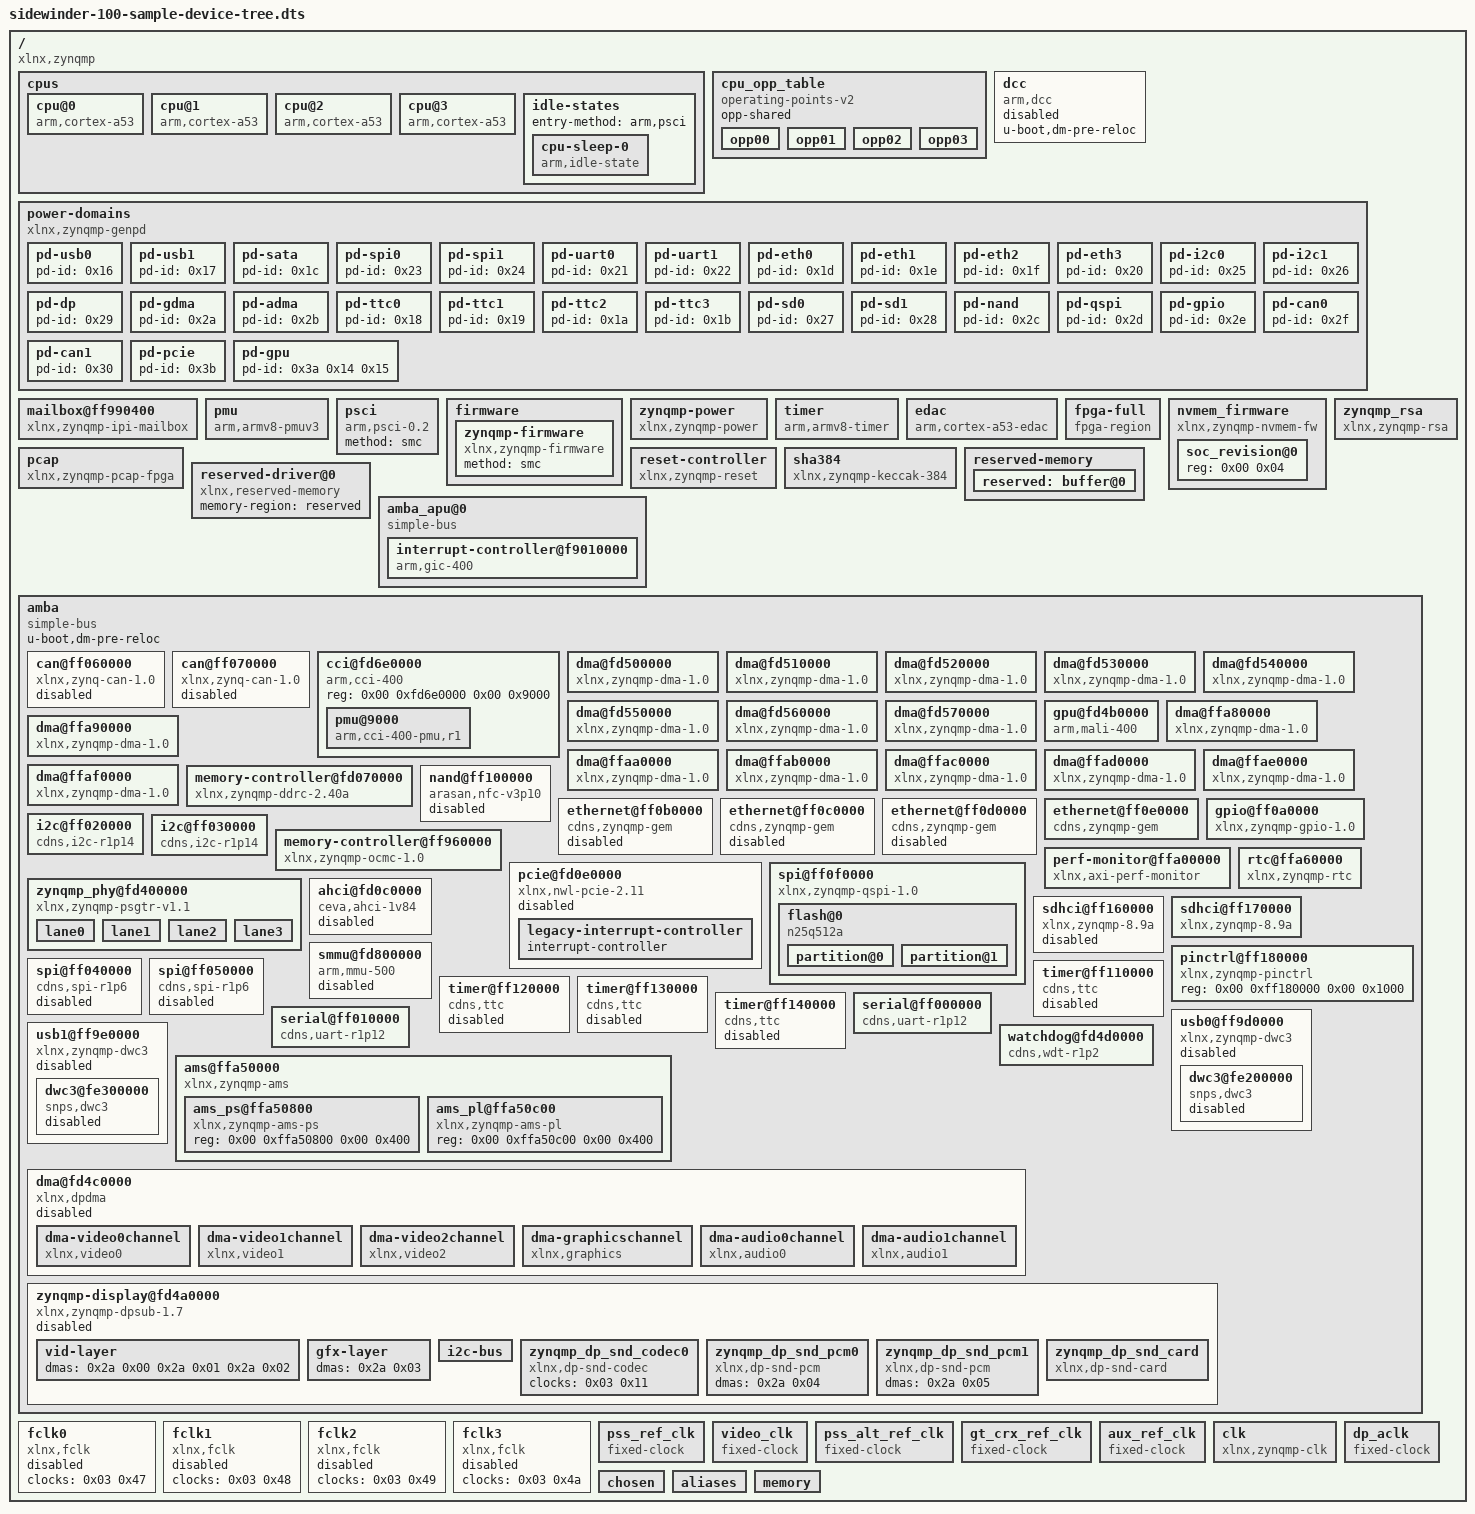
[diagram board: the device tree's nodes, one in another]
/dts-v1/;

/ {
	compatible = "xlnx,zynqmp";
	#address-cells = < 0x02 >;
	#size-cells = < 0x02 >;

	cpus {
		#address-cells = < 0x01 >;
		#size-cells = < 0x00 >;

		cpu@0 {
			compatible = "arm,cortex-a53\0arm,armv8";
			device_type = "cpu";
			enable-method = "psci";
			operating-points-v2 = < 0x01 >;
			reg = < 0x00 >;
			cpu-idle-states = < 0x02 >;
			clocks = < 0x03 0x0a >;
			phandle = < 0x33 >;
		};

		cpu@1 {
			compatible = "arm,cortex-a53\0arm,armv8";
			device_type = "cpu";
			enable-method = "psci";
			reg = < 0x01 >;
			operating-points-v2 = < 0x01 >;
			cpu-idle-states = < 0x02 >;
			phandle = < 0x34 >;
		};

		cpu@2 {
			compatible = "arm,cortex-a53\0arm,armv8";
			device_type = "cpu";
			enable-method = "psci";
			reg = < 0x02 >;
			operating-points-v2 = < 0x01 >;
			cpu-idle-states = < 0x02 >;
			phandle = < 0x35 >;
		};

		cpu@3 {
			compatible = "arm,cortex-a53\0arm,armv8";
			device_type = "cpu";
			enable-method = "psci";
			reg = < 0x03 >;
			operating-points-v2 = < 0x01 >;
			cpu-idle-states = < 0x02 >;
			phandle = < 0x36 >;
		};

		idle-states {
			entry-method = "arm,psci";

			cpu-sleep-0 {
				compatible = "arm,idle-state";
				arm,psci-suspend-param = < 0x40000000 >;
				local-timer-stop;
				entry-latency-us = < 0x12c >;
				exit-latency-us = < 0x258 >;
				min-residency-us = < 0x2710 >;
				phandle = < 0x02 >;
			};
		};
	};

	cpu_opp_table {
		compatible = "operating-points-v2";
		opp-shared;
		phandle = < 0x01 >;

		opp00 {
			opp-hz = < 0x00 0x47868bf4 >;
			opp-microvolt = < 0xf4240 >;
			clock-latency-ns = < 0x7a120 >;
		};

		opp01 {
			opp-hz = < 0x00 0x23c345fa >;
			opp-microvolt = < 0xf4240 >;
			clock-latency-ns = < 0x7a120 >;
		};

		opp02 {
			opp-hz = < 0x00 0x17d783fc >;
			opp-microvolt = < 0xf4240 >;
			clock-latency-ns = < 0x7a120 >;
		};

		opp03 {
			opp-hz = < 0x00 0x11e1a2fd >;
			opp-microvolt = < 0xf4240 >;
			clock-latency-ns = < 0x7a120 >;
		};
	};

	dcc {
		compatible = "arm,dcc";
		status = "disabled";
		u-boot,dm-pre-reloc;
		phandle = < 0x37 >;
	};

	power-domains {
		compatible = "xlnx,zynqmp-genpd";

		pd-usb0 {
			#power-domain-cells = < 0x00 >;
			pd-id = < 0x16 >;
			phandle = < 0x26 >;
		};

		pd-usb1 {
			#power-domain-cells = < 0x00 >;
			pd-id = < 0x17 >;
			phandle = < 0x27 >;
		};

		pd-sata {
			#power-domain-cells = < 0x00 >;
			pd-id = < 0x1c >;
			phandle = < 0x1b >;
		};

		pd-spi0 {
			#power-domain-cells = < 0x00 >;
			pd-id = < 0x23 >;
			phandle = < 0x1e >;
		};

		pd-spi1 {
			#power-domain-cells = < 0x00 >;
			pd-id = < 0x24 >;
			phandle = < 0x1f >;
		};

		pd-uart0 {
			#power-domain-cells = < 0x00 >;
			pd-id = < 0x21 >;
			phandle = < 0x24 >;
		};

		pd-uart1 {
			#power-domain-cells = < 0x00 >;
			pd-id = < 0x22 >;
			phandle = < 0x25 >;
		};

		pd-eth0 {
			#power-domain-cells = < 0x00 >;
			pd-id = < 0x1d >;
			phandle = < 0x0e >;
		};

		pd-eth1 {
			#power-domain-cells = < 0x00 >;
			pd-id = < 0x1e >;
			phandle = < 0x0f >;
		};

		pd-eth2 {
			#power-domain-cells = < 0x00 >;
			pd-id = < 0x1f >;
			phandle = < 0x10 >;
		};

		pd-eth3 {
			#power-domain-cells = < 0x00 >;
			pd-id = < 0x20 >;
			phandle = < 0x11 >;
		};

		pd-i2c0 {
			#power-domain-cells = < 0x00 >;
			pd-id = < 0x25 >;
			phandle = < 0x13 >;
		};

		pd-i2c1 {
			#power-domain-cells = < 0x00 >;
			pd-id = < 0x26 >;
			phandle = < 0x14 >;
		};

		pd-dp {
			#power-domain-cells = < 0x00 >;
			pd-id = < 0x29 >;
			phandle = < 0x28 >;
		};

		pd-gdma {
			#power-domain-cells = < 0x00 >;
			pd-id = < 0x2a >;
			phandle = < 0x0a >;
		};

		pd-adma {
			#power-domain-cells = < 0x00 >;
			pd-id = < 0x2b >;
			phandle = < 0x0c >;
		};

		pd-ttc0 {
			#power-domain-cells = < 0x00 >;
			pd-id = < 0x18 >;
			phandle = < 0x20 >;
		};

		pd-ttc1 {
			#power-domain-cells = < 0x00 >;
			pd-id = < 0x19 >;
			phandle = < 0x21 >;
		};

		pd-ttc2 {
			#power-domain-cells = < 0x00 >;
			pd-id = < 0x1a >;
			phandle = < 0x22 >;
		};

		pd-ttc3 {
			#power-domain-cells = < 0x00 >;
			pd-id = < 0x1b >;
			phandle = < 0x23 >;
		};

		pd-sd0 {
			#power-domain-cells = < 0x00 >;
			pd-id = < 0x27 >;
			phandle = < 0x1c >;
		};

		pd-sd1 {
			#power-domain-cells = < 0x00 >;
			pd-id = < 0x28 >;
			phandle = < 0x1d >;
		};

		pd-nand {
			#power-domain-cells = < 0x00 >;
			pd-id = < 0x2c >;
			phandle = < 0x0d >;
		};

		pd-qspi {
			#power-domain-cells = < 0x00 >;
			pd-id = < 0x2d >;
			phandle = < 0x18 >;
		};

		pd-gpio {
			#power-domain-cells = < 0x00 >;
			pd-id = < 0x2e >;
			phandle = < 0x12 >;
		};

		pd-can0 {
			#power-domain-cells = < 0x00 >;
			pd-id = < 0x2f >;
			phandle = < 0x07 >;
		};

		pd-can1 {
			#power-domain-cells = < 0x00 >;
			pd-id = < 0x30 >;
			phandle = < 0x08 >;
		};

		pd-pcie {
			#power-domain-cells = < 0x00 >;
			pd-id = < 0x3b >;
			phandle = < 0x17 >;
		};

		pd-gpu {
			#power-domain-cells = < 0x00 >;
			pd-id = < 0x3a 0x14 0x15 >;
			phandle = < 0x0b >;
		};
	};

	mailbox@ff990400 {
		compatible = "xlnx,zynqmp-ipi-mailbox";
		reg = < 0x00 0xff9905c0 0x00 0x20 0x00 0xff9905e0 0x00 0x20 0x00 0xff990e80 0x00 0x20 0x00 0xff990ea0 0x00 0x20 >;
		reg-names = "local_request_region\0local_response_region\0remote_request_region\0remote_response_region";
		#mbox-cells = < 0x01 >;
		xlnx,ipi-ids = < 0x00 0x04 >;
		interrupt-parent = < 0x04 >;
		interrupts = < 0x00 0x23 0x04 >;
		phandle = < 0x05 >;
	};

	pmu {
		compatible = "arm,armv8-pmuv3";
		interrupt-parent = < 0x04 >;
		interrupts = < 0x00 0x8f 0x04 0x00 0x90 0x04 0x00 0x91 0x04 0x00 0x92 0x04 >;
	};

	psci {
		compatible = "arm,psci-0.2";
		method = "smc";
	};

	firmware {

		zynqmp-firmware {
			compatible = "xlnx,zynqmp-firmware";
			method = "smc";
			phandle = < 0x38 >;
		};
	};

	zynqmp-power {
		compatible = "xlnx,zynqmp-power";
		mboxes = < 0x05 0x00 0x05 0x01 >;
		mbox-names = "tx\0rx";
		phandle = < 0x39 >;
	};

	timer {
		compatible = "arm,armv8-timer";
		interrupt-parent = < 0x04 >;
		interrupts = < 0x01 0x0d 0xf08 0x01 0x0e 0xf08 0x01 0x0b 0xf08 0x01 0x0a 0xf08 >;
	};

	edac {
		compatible = "arm,cortex-a53-edac";
	};

	fpga-full {
		compatible = "fpga-region";
        vendorName = "fidus.com";
        boardName = "sidewinder-100";
		fpga-mgr = < 0x06 >;
		#address-cells = < 0x02 >;
		#size-cells = < 0x02 >;
		phandle = < 0x3a >;
	};

	nvmem_firmware {
		compatible = "xlnx,zynqmp-nvmem-fw";
		#address-cells = < 0x01 >;
		#size-cells = < 0x01 >;

		soc_revision@0 {
			reg = < 0x00 0x04 >;
			phandle = < 0x19 >;
		};
	};

	pcap {
		compatible = "xlnx,zynqmp-pcap-fpga";
		phandle = < 0x06 >;
	};

	reset-controller {
		compatible = "xlnx,zynqmp-reset";
		#reset-cells = < 0x01 >;
		phandle = < 0x1a >;
	};

	zynqmp_rsa {
		compatible = "xlnx,zynqmp-rsa";
		phandle = < 0x3b >;
	};

	sha384 {
		compatible = "xlnx,zynqmp-keccak-384";
		phandle = < 0x3c >;
	};

	reserved-memory {
		#address-cells = <2>;
		#size-cells = <2>;
		ranges;
		
		reserved: buffer@0 {
			no-map;
			reg = <0x0 0x90000000 0x0 0x10000000>;
		};
	};
	
    reserved-driver@0 {
		compatible = "xlnx,reserved-memory";
		memory-region = <&reserved>;
	};

	amba_apu@0 {
		compatible = "simple-bus";
		#address-cells = < 0x02 >;
		#size-cells = < 0x01 >;
		ranges = < 0x00 0x00 0x00 0x00 0xffffffff >;
		phandle = < 0x3d >;

		interrupt-controller@f9010000 {
			compatible = "arm,gic-400\0arm,cortex-a15-gic";
			#interrupt-cells = < 0x03 >;
			reg = < 0x00 0xf9010000 0x10000 0x00 0xf9020000 0x20000 0x00 0xf9040000 0x20000 0x00 0xf9060000 0x20000 >;
			interrupt-controller;
			interrupt-parent = < 0x04 >;
			interrupts = < 0x01 0x09 0xf04 >;
			phandle = < 0x04 >;
		};
	};

	amba {
		compatible = "simple-bus";
		u-boot,dm-pre-reloc;
		#address-cells = < 0x02 >;
		#size-cells = < 0x02 >;
		ranges;
		phandle = < 0x3e >;

		can@ff060000 {
			compatible = "xlnx,zynq-can-1.0";
			status = "disabled";
			clock-names = "can_clk\0pclk";
			reg = < 0x00 0xff060000 0x00 0x1000 >;
			interrupts = < 0x00 0x17 0x04 >;
			interrupt-parent = < 0x04 >;
			tx-fifo-depth = < 0x40 >;
			rx-fifo-depth = < 0x40 >;
			power-domains = < 0x07 >;
			clocks = < 0x03 0x3f 0x03 0x1f >;
			phandle = < 0x3f >;
		};

		can@ff070000 {
			compatible = "xlnx,zynq-can-1.0";
			status = "disabled";
			clock-names = "can_clk\0pclk";
			reg = < 0x00 0xff070000 0x00 0x1000 >;
			interrupts = < 0x00 0x18 0x04 >;
			interrupt-parent = < 0x04 >;
			tx-fifo-depth = < 0x40 >;
			rx-fifo-depth = < 0x40 >;
			power-domains = < 0x08 >;
			clocks = < 0x03 0x40 0x03 0x1f >;
			phandle = < 0x40 >;
		};

		cci@fd6e0000 {
			compatible = "arm,cci-400";
			reg = < 0x00 0xfd6e0000 0x00 0x9000 >;
			ranges = < 0x00 0x00 0xfd6e0000 0x10000 >;
			#address-cells = < 0x01 >;
			#size-cells = < 0x01 >;
			phandle = < 0x41 >;

			pmu@9000 {
				compatible = "arm,cci-400-pmu,r1";
				reg = < 0x9000 0x5000 >;
				interrupt-parent = < 0x04 >;
				interrupts = < 0x00 0x7b 0x04 0x00 0x7b 0x04 0x00 0x7b 0x04 0x00 0x7b 0x04 0x00 0x7b 0x04 >;
			};
		};

		dma@fd500000 {
			status = "okay";
			compatible = "xlnx,zynqmp-dma-1.0";
			reg = < 0x00 0xfd500000 0x00 0x1000 >;
			interrupt-parent = < 0x04 >;
			interrupts = < 0x00 0x7c 0x04 >;
			clock-names = "clk_main\0clk_apb";
			xlnx,bus-width = < 0x80 >;
			#stream-id-cells = < 0x01 >;
			iommus = < 0x09 0x14e8 >;
			power-domains = < 0x0a >;
			clocks = < 0x03 0x13 0x03 0x1f >;
			phandle = < 0x42 >;
		};

		dma@fd510000 {
			status = "okay";
			compatible = "xlnx,zynqmp-dma-1.0";
			reg = < 0x00 0xfd510000 0x00 0x1000 >;
			interrupt-parent = < 0x04 >;
			interrupts = < 0x00 0x7d 0x04 >;
			clock-names = "clk_main\0clk_apb";
			xlnx,bus-width = < 0x80 >;
			#stream-id-cells = < 0x01 >;
			iommus = < 0x09 0x14e9 >;
			power-domains = < 0x0a >;
			clocks = < 0x03 0x13 0x03 0x1f >;
			phandle = < 0x43 >;
		};

		dma@fd520000 {
			status = "okay";
			compatible = "xlnx,zynqmp-dma-1.0";
			reg = < 0x00 0xfd520000 0x00 0x1000 >;
			interrupt-parent = < 0x04 >;
			interrupts = < 0x00 0x7e 0x04 >;
			clock-names = "clk_main\0clk_apb";
			xlnx,bus-width = < 0x80 >;
			#stream-id-cells = < 0x01 >;
			iommus = < 0x09 0x14ea >;
			power-domains = < 0x0a >;
			clocks = < 0x03 0x13 0x03 0x1f >;
			phandle = < 0x44 >;
		};

		dma@fd530000 {
			status = "okay";
			compatible = "xlnx,zynqmp-dma-1.0";
			reg = < 0x00 0xfd530000 0x00 0x1000 >;
			interrupt-parent = < 0x04 >;
			interrupts = < 0x00 0x7f 0x04 >;
			clock-names = "clk_main\0clk_apb";
			xlnx,bus-width = < 0x80 >;
			#stream-id-cells = < 0x01 >;
			iommus = < 0x09 0x14eb >;
			power-domains = < 0x0a >;
			clocks = < 0x03 0x13 0x03 0x1f >;
			phandle = < 0x45 >;
		};

		dma@fd540000 {
			status = "okay";
			compatible = "xlnx,zynqmp-dma-1.0";
			reg = < 0x00 0xfd540000 0x00 0x1000 >;
			interrupt-parent = < 0x04 >;
			interrupts = < 0x00 0x80 0x04 >;
			clock-names = "clk_main\0clk_apb";
			xlnx,bus-width = < 0x80 >;
			#stream-id-cells = < 0x01 >;
			iommus = < 0x09 0x14ec >;
			power-domains = < 0x0a >;
			clocks = < 0x03 0x13 0x03 0x1f >;
			phandle = < 0x46 >;
		};

		dma@fd550000 {
			status = "okay";
			compatible = "xlnx,zynqmp-dma-1.0";
			reg = < 0x00 0xfd550000 0x00 0x1000 >;
			interrupt-parent = < 0x04 >;
			interrupts = < 0x00 0x81 0x04 >;
			clock-names = "clk_main\0clk_apb";
			xlnx,bus-width = < 0x80 >;
			#stream-id-cells = < 0x01 >;
			iommus = < 0x09 0x14ed >;
			power-domains = < 0x0a >;
			clocks = < 0x03 0x13 0x03 0x1f >;
			phandle = < 0x47 >;
		};

		dma@fd560000 {
			status = "okay";
			compatible = "xlnx,zynqmp-dma-1.0";
			reg = < 0x00 0xfd560000 0x00 0x1000 >;
			interrupt-parent = < 0x04 >;
			interrupts = < 0x00 0x82 0x04 >;
			clock-names = "clk_main\0clk_apb";
			xlnx,bus-width = < 0x80 >;
			#stream-id-cells = < 0x01 >;
			iommus = < 0x09 0x14ee >;
			power-domains = < 0x0a >;
			clocks = < 0x03 0x13 0x03 0x1f >;
			phandle = < 0x48 >;
		};

		dma@fd570000 {
			status = "okay";
			compatible = "xlnx,zynqmp-dma-1.0";
			reg = < 0x00 0xfd570000 0x00 0x1000 >;
			interrupt-parent = < 0x04 >;
			interrupts = < 0x00 0x83 0x04 >;
			clock-names = "clk_main\0clk_apb";
			xlnx,bus-width = < 0x80 >;
			#stream-id-cells = < 0x01 >;
			iommus = < 0x09 0x14ef >;
			power-domains = < 0x0a >;
			clocks = < 0x03 0x13 0x03 0x1f >;
			phandle = < 0x49 >;
		};

		gpu@fd4b0000 {
			status = "okay";
			compatible = "arm,mali-400\0arm,mali-utgard";
			reg = < 0x00 0xfd4b0000 0x00 0x10000 >;
			interrupt-parent = < 0x04 >;
			interrupts = < 0x00 0x84 0x04 0x00 0x84 0x04 0x00 0x84 0x04 0x00 0x84 0x04 0x00 0x84 0x04 0x00 0x84 0x04 >;
			interrupt-names = "IRQGP\0IRQGPMMU\0IRQPP0\0IRQPPMMU0\0IRQPP1\0IRQPPMMU1";
			clock-names = "gpu\0gpu_pp0\0gpu_pp1";
			power-domains = < 0x0b >;
			clocks = < 0x03 0x18 0x03 0x19 0x03 0x1a >;
			phandle = < 0x4a >;
		};

		dma@ffa80000 {
			status = "okay";
			compatible = "xlnx,zynqmp-dma-1.0";
			reg = < 0x00 0xffa80000 0x00 0x1000 >;
			interrupt-parent = < 0x04 >;
			interrupts = < 0x00 0x4d 0x04 >;
			clock-names = "clk_main\0clk_apb";
			xlnx,bus-width = < 0x40 >;
			#stream-id-cells = < 0x01 >;
			power-domains = < 0x0c >;
			clocks = < 0x03 0x44 0x03 0x1f >;
			phandle = < 0x4b >;
		};

		dma@ffa90000 {
			status = "okay";
			compatible = "xlnx,zynqmp-dma-1.0";
			reg = < 0x00 0xffa90000 0x00 0x1000 >;
			interrupt-parent = < 0x04 >;
			interrupts = < 0x00 0x4e 0x04 >;
			clock-names = "clk_main\0clk_apb";
			xlnx,bus-width = < 0x40 >;
			#stream-id-cells = < 0x01 >;
			power-domains = < 0x0c >;
			clocks = < 0x03 0x44 0x03 0x1f >;
			phandle = < 0x4c >;
		};

		dma@ffaa0000 {
			status = "okay";
			compatible = "xlnx,zynqmp-dma-1.0";
			reg = < 0x00 0xffaa0000 0x00 0x1000 >;
			interrupt-parent = < 0x04 >;
			interrupts = < 0x00 0x4f 0x04 >;
			clock-names = "clk_main\0clk_apb";
			xlnx,bus-width = < 0x40 >;
			#stream-id-cells = < 0x01 >;
			power-domains = < 0x0c >;
			clocks = < 0x03 0x44 0x03 0x1f >;
			phandle = < 0x4d >;
		};

		dma@ffab0000 {
			status = "okay";
			compatible = "xlnx,zynqmp-dma-1.0";
			reg = < 0x00 0xffab0000 0x00 0x1000 >;
			interrupt-parent = < 0x04 >;
			interrupts = < 0x00 0x50 0x04 >;
			clock-names = "clk_main\0clk_apb";
			xlnx,bus-width = < 0x40 >;
			#stream-id-cells = < 0x01 >;
			power-domains = < 0x0c >;
			clocks = < 0x03 0x44 0x03 0x1f >;
			phandle = < 0x4e >;
		};

		dma@ffac0000 {
			status = "okay";
			compatible = "xlnx,zynqmp-dma-1.0";
			reg = < 0x00 0xffac0000 0x00 0x1000 >;
			interrupt-parent = < 0x04 >;
			interrupts = < 0x00 0x51 0x04 >;
			clock-names = "clk_main\0clk_apb";
			xlnx,bus-width = < 0x40 >;
			#stream-id-cells = < 0x01 >;
			power-domains = < 0x0c >;
			clocks = < 0x03 0x44 0x03 0x1f >;
			phandle = < 0x4f >;
		};

		dma@ffad0000 {
			status = "okay";
			compatible = "xlnx,zynqmp-dma-1.0";
			reg = < 0x00 0xffad0000 0x00 0x1000 >;
			interrupt-parent = < 0x04 >;
			interrupts = < 0x00 0x52 0x04 >;
			clock-names = "clk_main\0clk_apb";
			xlnx,bus-width = < 0x40 >;
			#stream-id-cells = < 0x01 >;
			power-domains = < 0x0c >;
			clocks = < 0x03 0x44 0x03 0x1f >;
			phandle = < 0x50 >;
		};

		dma@ffae0000 {
			status = "okay";
			compatible = "xlnx,zynqmp-dma-1.0";
			reg = < 0x00 0xffae0000 0x00 0x1000 >;
			interrupt-parent = < 0x04 >;
			interrupts = < 0x00 0x53 0x04 >;
			clock-names = "clk_main\0clk_apb";
			xlnx,bus-width = < 0x40 >;
			#stream-id-cells = < 0x01 >;
			power-domains = < 0x0c >;
			clocks = < 0x03 0x44 0x03 0x1f >;
			phandle = < 0x51 >;
		};

		dma@ffaf0000 {
			status = "okay";
			compatible = "xlnx,zynqmp-dma-1.0";
			reg = < 0x00 0xffaf0000 0x00 0x1000 >;
			interrupt-parent = < 0x04 >;
			interrupts = < 0x00 0x54 0x04 >;
			clock-names = "clk_main\0clk_apb";
			xlnx,bus-width = < 0x40 >;
			#stream-id-cells = < 0x01 >;
			power-domains = < 0x0c >;
			clocks = < 0x03 0x44 0x03 0x1f >;
			phandle = < 0x52 >;
		};

		memory-controller@fd070000 {
			compatible = "xlnx,zynqmp-ddrc-2.40a";
			reg = < 0x00 0xfd070000 0x00 0x30000 >;
			interrupt-parent = < 0x04 >;
			interrupts = < 0x00 0x70 0x04 >;
			phandle = < 0x53 >;
		};

		nand@ff100000 {
			compatible = "arasan,nfc-v3p10";
			status = "disabled";
			reg = < 0x00 0xff100000 0x00 0x1000 >;
			clock-names = "clk_sys\0clk_flash";
			interrupt-parent = < 0x04 >;
			interrupts = < 0x00 0x0e 0x04 >;
			#address-cells = < 0x01 >;
			#size-cells = < 0x00 >;
			#stream-id-cells = < 0x01 >;
			iommus = < 0x09 0x872 >;
			power-domains = < 0x0d >;
			clocks = < 0x03 0x3c 0x03 0x1f >;
			phandle = < 0x54 >;
		};

		ethernet@ff0b0000 {
			compatible = "cdns,zynqmp-gem";
			status = "disabled";
			interrupt-parent = < 0x04 >;
			interrupts = < 0x00 0x39 0x04 0x00 0x39 0x04 >;
			reg = < 0x00 0xff0b0000 0x00 0x1000 >;
			clock-names = "pclk\0hclk\0tx_clk\0rx_clk\0tsu_clk";
			#address-cells = < 0x01 >;
			#size-cells = < 0x00 >;
			#stream-id-cells = < 0x01 >;
			iommus = < 0x09 0x874 >;
			power-domains = < 0x0e >;
			clocks = < 0x03 0x1f 0x03 0x31 0x03 0x2d 0x03 0x31 0x03 0x2c >;
			phandle = < 0x55 >;
		};

		ethernet@ff0c0000 {
			compatible = "cdns,zynqmp-gem";
			status = "disabled";
			interrupt-parent = < 0x04 >;
			interrupts = < 0x00 0x3b 0x04 0x00 0x3b 0x04 >;
			reg = < 0x00 0xff0c0000 0x00 0x1000 >;
			clock-names = "pclk\0hclk\0tx_clk\0rx_clk\0tsu_clk";
			#address-cells = < 0x01 >;
			#size-cells = < 0x00 >;
			#stream-id-cells = < 0x01 >;
			iommus = < 0x09 0x875 >;
			power-domains = < 0x0f >;
			clocks = < 0x03 0x1f 0x03 0x32 0x03 0x2e 0x03 0x32 0x03 0x2c >;
			phandle = < 0x56 >;
		};

		ethernet@ff0d0000 {
			compatible = "cdns,zynqmp-gem";
			status = "disabled";
			interrupt-parent = < 0x04 >;
			interrupts = < 0x00 0x3d 0x04 0x00 0x3d 0x04 >;
			reg = < 0x00 0xff0d0000 0x00 0x1000 >;
			clock-names = "pclk\0hclk\0tx_clk\0rx_clk\0tsu_clk";
			#address-cells = < 0x01 >;
			#size-cells = < 0x00 >;
			#stream-id-cells = < 0x01 >;
			iommus = < 0x09 0x876 >;
			power-domains = < 0x10 >;
			clocks = < 0x03 0x1f 0x03 0x33 0x03 0x2f 0x03 0x33 0x03 0x2c >;
			phandle = < 0x57 >;
		};

		ethernet@ff0e0000 {
			compatible = "cdns,zynqmp-gem";
			status = "okay";
			interrupt-parent = < 0x04 >;
			interrupts = < 0x00 0x3f 0x04 0x00 0x3f 0x04 >;
			reg = < 0x00 0xff0e0000 0x00 0x1000 >;
			clock-names = "pclk\0hclk\0tx_clk\0rx_clk\0tsu_clk";
			#address-cells = < 0x01 >;
			#size-cells = < 0x00 >;
			#stream-id-cells = < 0x01 >;
			iommus = < 0x09 0x877 >;
			power-domains = < 0x11 >;
			clocks = < 0x03 0x1f 0x03 0x34 0x03 0x30 0x03 0x34 0x03 0x2c >;
			phy-mode = "rgmii-id";
			xlnx,ptp-enet-clock = < 0x00 >;
			phandle = < 0x58 >;
		};

		gpio@ff0a0000 {
			compatible = "xlnx,zynqmp-gpio-1.0";
			status = "okay";
			#gpio-cells = < 0x02 >;
			interrupt-parent = < 0x04 >;
			interrupts = < 0x00 0x10 0x04 >;
			interrupt-controller;
			#interrupt-cells = < 0x02 >;
			reg = < 0x00 0xff0a0000 0x00 0x1000 >;
			gpio-controller;
			power-domains = < 0x12 >;
			clocks = < 0x03 0x1f >;
			emio-gpio-width = < 0x20 >;
			gpio-mask-high = < 0x00 >;
			gpio-mask-low = < 0x5600 >;
			phandle = < 0x59 >;
		};

		i2c@ff020000 {
			compatible = "cdns,i2c-r1p14\0cdns,i2c-r1p10";
			status = "okay";
			interrupt-parent = < 0x04 >;
			interrupts = < 0x00 0x11 0x04 >;
			reg = < 0x00 0xff020000 0x00 0x1000 >;
			#address-cells = < 0x01 >;
			#size-cells = < 0x00 >;
			power-domains = < 0x13 >;
			clocks = < 0x03 0x3d >;
			clock-frequency = < 0x61a80 >;
			phandle = < 0x5a >;
		};

		i2c@ff030000 {
			compatible = "cdns,i2c-r1p14\0cdns,i2c-r1p10";
			status = "okay";
			interrupt-parent = < 0x04 >;
			interrupts = < 0x00 0x12 0x04 >;
			reg = < 0x00 0xff030000 0x00 0x1000 >;
			#address-cells = < 0x01 >;
			#size-cells = < 0x00 >;
			power-domains = < 0x14 >;
			clocks = < 0x03 0x3e >;
			clock-frequency = < 0x61a80 >;
			phandle = < 0x5b >;
		};

		memory-controller@ff960000 {
			compatible = "xlnx,zynqmp-ocmc-1.0";
			reg = < 0x00 0xff960000 0x00 0x1000 >;
			interrupt-parent = < 0x04 >;
			interrupts = < 0x00 0x0a 0x04 >;
			phandle = < 0x5c >;
		};

		perf-monitor@ffa00000 {
			compatible = "xlnx,axi-perf-monitor";
			reg = < 0x00 0xffa00000 0x00 0x10000 >;
			interrupts = < 0x00 0x19 0x04 >;
			interrupt-parent = < 0x04 >;
			xlnx,enable-profile = < 0x00 >;
			xlnx,enable-trace = < 0x00 >;
			xlnx,num-monitor-slots = < 0x01 >;
			xlnx,enable-event-count = < 0x01 >;
			xlnx,enable-event-log = < 0x00 >;
			xlnx,have-sampled-metric-cnt = < 0x01 >;
			xlnx,num-of-counters = < 0x03 >;
			xlnx,metric-count-width = < 0x20 >;
			xlnx,metrics-sample-count-width = < 0x20 >;
			xlnx,global-count-width = < 0x20 >;
			xlnx,metric-count-scale = < 0x01 >;
			clocks = < 0x03 0x1f >;
			xlnx,enable-32bit-filter-id = < 0x01 >;
			xlnx,enable-advanced = < 0x01 >;
			xlnx,fifo-axis-depth = < 0x20 >;
			xlnx,fifo-axis-tdata-width = < 0x38 >;
			xlnx,fifo-axis-tid-width = < 0x01 >;
			phandle = < 0x5d >;
		};

		pcie@fd0e0000 {
			compatible = "xlnx,nwl-pcie-2.11";
			status = "disabled";
			#address-cells = < 0x03 >;
			#size-cells = < 0x02 >;
			#interrupt-cells = < 0x01 >;
			msi-controller;
			device_type = "pci";
			interrupt-parent = < 0x04 >;
			interrupts = < 0x00 0x76 0x04 0x00 0x75 0x04 0x00 0x74 0x04 0x00 0x73 0x04 0x00 0x72 0x04 >;
			interrupt-names = "misc\0dummy\0intx\0msi1\0msi0";
			msi-parent = < 0x15 >;
			reg = < 0x00 0xfd0e0000 0x00 0x1000 0x00 0xfd480000 0x00 0x1000 0x80 0x00 0x00 0x1000000 >;
			reg-names = "breg\0pcireg\0cfg";
			ranges = < 0x2000000 0x00 0xe0000000 0x00 0xe0000000 0x00 0x10000000 0x43000000 0x06 0x00 0x06 0x00 0x02 0x00 >;
			interrupt-map-mask = < 0x00 0x00 0x00 0x07 >;
			bus-range = < 0x00 0xff >;
			interrupt-map = < 0x00 0x00 0x00 0x01 0x16 0x01 0x00 0x00 0x00 0x02 0x16 0x02 0x00 0x00 0x00 0x03 0x16 0x03 0x00 0x00 0x00 0x04 0x16 0x04 >;
			power-domains = < 0x17 >;
			clocks = < 0x03 0x17 >;
			phandle = < 0x15 >;

			legacy-interrupt-controller {
				interrupt-controller;
				#address-cells = < 0x00 >;
				#interrupt-cells = < 0x01 >;
				phandle = < 0x16 >;
			};
		};

		spi@ff0f0000 {
			u-boot,dm-pre-reloc;
			compatible = "xlnx,zynqmp-qspi-1.0";
			status = "okay";
			clock-names = "ref_clk\0pclk";
			interrupts = < 0x00 0x0f 0x04 >;
			interrupt-parent = < 0x04 >;
			num-cs = < 0x01 >;
			reg = < 0x00 0xff0f0000 0x00 0x1000 0x00 0xc0000000 0x00 0x8000000 >;
			#address-cells = < 0x01 >;
			#size-cells = < 0x00 >;
			#stream-id-cells = < 0x01 >;
			iommus = < 0x09 0x873 >;
			power-domains = < 0x18 >;
			clocks = < 0x03 0x35 0x03 0x1f >;
			is-dual = < 0x01 >;
			spi-rx-bus-width = < 0x04 >;
			spi-tx-bus-width = < 0x04 >;
			phandle = < 0x5e >;

			flash@0 {
				compatible = "n25q512a\0micron,m25p80";
				spi-tx-bus-width = < 0x01 >;
				spi-rx-bus-width = < 0x04 >;
				reg = < 0x00 >;
				#address-cells = < 0x01 >;
				#size-cells = < 0x01 >;
				spi-max-frequency = < 0x66ff300 >;

				partition@0 {
					label = "boot";
					reg = < 0x00 0x100000 >;
				};

				partition@1 {
					label = "bootenv";
					reg = < 0x100000 0x40000 >;
				};
			};
		};

		rtc@ffa60000 {
			compatible = "xlnx,zynqmp-rtc";
			status = "okay";
			reg = < 0x00 0xffa60000 0x00 0x100 >;
			interrupt-parent = < 0x04 >;
			interrupts = < 0x00 0x1a 0x04 0x00 0x1b 0x04 >;
			interrupt-names = "alarm\0sec";
			calibration = < 0x8000 >;
			phandle = < 0x5f >;
		};

		zynqmp_phy@fd400000 {
			compatible = "xlnx,zynqmp-psgtr-v1.1";
			status = "okay";
			reg = < 0x00 0xfd400000 0x00 0x40000 0x00 0xfd3d0000 0x00 0x1000 >;
			reg-names = "serdes\0siou";
			nvmem-cells = < 0x19 >;
			nvmem-cell-names = "soc_revision";
			resets = < 0x1a 0x10 0x1a 0x3b 0x1a 0x3c 0x1a 0x3d 0x1a 0x3e 0x1a 0x3f 0x1a 0x40 0x1a 0x03 0x1a 0x1d 0x1a 0x1e 0x1a 0x1f 0x1a 0x20 >;
			reset-names = "sata_rst\0usb0_crst\0usb1_crst\0usb0_hibrst\0usb1_hibrst\0usb0_apbrst\0usb1_apbrst\0dp_rst\0gem0_rst\0gem1_rst\0gem2_rst\0gem3_rst";
			phandle = < 0x60 >;

			lane0 {
				#phy-cells = < 0x04 >;
				phandle = < 0x61 >;
			};

			lane1 {
				#phy-cells = < 0x04 >;
				phandle = < 0x62 >;
			};

			lane2 {
				#phy-cells = < 0x04 >;
				phandle = < 0x63 >;
			};

			lane3 {
				#phy-cells = < 0x04 >;
				phandle = < 0x64 >;
			};
		};

		ahci@fd0c0000 {
			compatible = "ceva,ahci-1v84";
			status = "disabled";
			reg = < 0x00 0xfd0c0000 0x00 0x2000 >;
			interrupt-parent = < 0x04 >;
			interrupts = < 0x00 0x85 0x04 >;
			power-domains = < 0x1b >;
			#stream-id-cells = < 0x04 >;
			iommus = < 0x09 0x4c0 0x09 0x4c1 0x09 0x4c2 0x09 0x4c3 >;
			clocks = < 0x03 0x16 >;
			phandle = < 0x65 >;
		};

		sdhci@ff160000 {
			u-boot,dm-pre-reloc;
			compatible = "xlnx,zynqmp-8.9a\0arasan,sdhci-8.9a";
			status = "disabled";
			interrupt-parent = < 0x04 >;
			interrupts = < 0x00 0x30 0x04 >;
			reg = < 0x00 0xff160000 0x00 0x1000 >;
			clock-names = "clk_xin\0clk_ahb";
			xlnx,device_id = < 0x00 >;
			#stream-id-cells = < 0x01 >;
			iommus = < 0x09 0x870 >;
			power-domains = < 0x1c >;
			clocks = < 0x03 0x36 0x03 0x1f >;
			phandle = < 0x66 >;
		};

		sdhci@ff170000 {
			u-boot,dm-pre-reloc;
			compatible = "xlnx,zynqmp-8.9a\0arasan,sdhci-8.9a";
			status = "okay";
			interrupt-parent = < 0x04 >;
			interrupts = < 0x00 0x31 0x04 >;
			reg = < 0x00 0xff170000 0x00 0x1000 >;
			clock-names = "clk_xin\0clk_ahb";
			xlnx,device_id = < 0x01 >;
			#stream-id-cells = < 0x01 >;
			iommus = < 0x09 0x871 >;
			power-domains = < 0x1d >;
			clocks = < 0x03 0x37 0x03 0x1f >;
			clock-frequency = < 0xbebba30 >;
			xlnx,mio_bank = < 0x01 >;
			no-1-8-v;
			wp-inverted;
			phandle = < 0x67 >;
		};

		pinctrl@ff180000 {
			compatible = "xlnx,zynqmp-pinctrl";
			status = "okay";
			reg = < 0x00 0xff180000 0x00 0x1000 >;
			phandle = < 0x68 >;
		};

		smmu@fd800000 {
			compatible = "arm,mmu-500";
			reg = < 0x00 0xfd800000 0x00 0x20000 >;
			#iommu-cells = < 0x01 >;
			status = "disabled";
			#global-interrupts = < 0x01 >;
			interrupt-parent = < 0x04 >;
			interrupts = < 0x00 0x9b 0x04 0x00 0x9b 0x04 0x00 0x9b 0x04 0x00 0x9b 0x04 0x00 0x9b 0x04 0x00 0x9b 0x04 0x00 0x9b 0x04 0x00 0x9b 0x04 0x00 0x9b 0x04 0x00 0x9b 0x04 0x00 0x9b 0x04 0x00 0x9b 0x04 0x00 0x9b 0x04 0x00 0x9b 0x04 0x00 0x9b 0x04 0x00 0x9b 0x04 0x00 0x9b 0x04 >;
			phandle = < 0x09 >;
		};

		spi@ff040000 {
			compatible = "cdns,spi-r1p6";
			status = "disabled";
			interrupt-parent = < 0x04 >;
			interrupts = < 0x00 0x13 0x04 >;
			reg = < 0x00 0xff040000 0x00 0x1000 >;
			clock-names = "ref_clk\0pclk";
			#address-cells = < 0x01 >;
			#size-cells = < 0x00 >;
			power-domains = < 0x1e >;
			clocks = < 0x03 0x3a 0x03 0x1f >;
			phandle = < 0x69 >;
		};

		spi@ff050000 {
			compatible = "cdns,spi-r1p6";
			status = "disabled";
			interrupt-parent = < 0x04 >;
			interrupts = < 0x00 0x14 0x04 >;
			reg = < 0x00 0xff050000 0x00 0x1000 >;
			clock-names = "ref_clk\0pclk";
			#address-cells = < 0x01 >;
			#size-cells = < 0x00 >;
			power-domains = < 0x1f >;
			clocks = < 0x03 0x3b 0x03 0x1f >;
			phandle = < 0x6a >;
		};

		timer@ff110000 {
			compatible = "cdns,ttc";
			status = "disabled";
			interrupt-parent = < 0x04 >;
			interrupts = < 0x00 0x24 0x04 0x00 0x25 0x04 0x00 0x26 0x04 >;
			reg = < 0x00 0xff110000 0x00 0x1000 >;
			timer-width = < 0x20 >;
			power-domains = < 0x20 >;
			phandle = < 0x6b >;
		};

		timer@ff120000 {
			compatible = "cdns,ttc";
			status = "disabled";
			interrupt-parent = < 0x04 >;
			interrupts = < 0x00 0x27 0x04 0x00 0x28 0x04 0x00 0x29 0x04 >;
			reg = < 0x00 0xff120000 0x00 0x1000 >;
			timer-width = < 0x20 >;
			power-domains = < 0x21 >;
			phandle = < 0x6c >;
		};

		timer@ff130000 {
			compatible = "cdns,ttc";
			status = "disabled";
			interrupt-parent = < 0x04 >;
			interrupts = < 0x00 0x2a 0x04 0x00 0x2b 0x04 0x00 0x2c 0x04 >;
			reg = < 0x00 0xff130000 0x00 0x1000 >;
			timer-width = < 0x20 >;
			power-domains = < 0x22 >;
			phandle = < 0x6d >;
		};

		timer@ff140000 {
			compatible = "cdns,ttc";
			status = "disabled";
			interrupt-parent = < 0x04 >;
			interrupts = < 0x00 0x2d 0x04 0x00 0x2e 0x04 0x00 0x2f 0x04 >;
			reg = < 0x00 0xff140000 0x00 0x1000 >;
			timer-width = < 0x20 >;
			power-domains = < 0x23 >;
			phandle = < 0x6e >;
		};

		serial@ff000000 {
			u-boot,dm-pre-reloc;
			compatible = "cdns,uart-r1p12\0xlnx,xuartps";
			status = "okay";
			interrupt-parent = < 0x04 >;
			interrupts = < 0x00 0x15 0x04 >;
			reg = < 0x00 0xff000000 0x00 0x1000 >;
			clock-names = "uart_clk\0pclk";
			power-domains = < 0x24 >;
			clocks = < 0x03 0x38 0x03 0x1f >;
			device_type = "serial";
			port-number = < 0x00 >;
			phandle = < 0x6f >;
		};

		serial@ff010000 {
			u-boot,dm-pre-reloc;
			compatible = "cdns,uart-r1p12\0xlnx,xuartps";
			status = "okay";
			interrupt-parent = < 0x04 >;
			interrupts = < 0x00 0x16 0x04 >;
			reg = < 0x00 0xff010000 0x00 0x1000 >;
			clock-names = "uart_clk\0pclk";
			power-domains = < 0x25 >;
			clocks = < 0x03 0x39 0x03 0x1f >;
			device_type = "serial";
			port-number = < 0x01 >;
			phandle = < 0x70 >;
		};

		usb0@ff9d0000 {
			#address-cells = < 0x02 >;
			#size-cells = < 0x02 >;
			status = "disabled";
			compatible = "xlnx,zynqmp-dwc3";
			reg = < 0x00 0xff9d0000 0x00 0x100 >;
			clock-names = "bus_clk\0ref_clk";
			power-domains = < 0x26 >;
			ranges;
			nvmem-cells = < 0x19 >;
			nvmem-cell-names = "soc_revision";
			clocks = < 0x03 0x20 0x03 0x22 >;
			phandle = < 0x71 >;

			dwc3@fe200000 {
				compatible = "snps,dwc3";
				status = "disabled";
				reg = < 0x00 0xfe200000 0x00 0x40000 >;
				interrupt-parent = < 0x04 >;
				interrupts = < 0x00 0x41 0x04 0x00 0x45 0x04 0x00 0x4b 0x04 >;
				#stream-id-cells = < 0x01 >;
				iommus = < 0x09 0x860 >;
				snps,quirk-frame-length-adjustment = < 0x20 >;
				snps,refclk_fladj;
				snps,enable_guctl1_resume_quirk;
				snps,enable_guctl1_ipd_quirk;
				snps,xhci-stream-quirk;
				phandle = < 0x72 >;
			};
		};

		usb1@ff9e0000 {
			#address-cells = < 0x02 >;
			#size-cells = < 0x02 >;
			status = "disabled";
			compatible = "xlnx,zynqmp-dwc3";
			reg = < 0x00 0xff9e0000 0x00 0x100 >;
			clock-names = "bus_clk\0ref_clk";
			power-domains = < 0x27 >;
			ranges;
			nvmem-cells = < 0x19 >;
			nvmem-cell-names = "soc_revision";
			clocks = < 0x03 0x21 0x03 0x22 >;
			phandle = < 0x73 >;

			dwc3@fe300000 {
				compatible = "snps,dwc3";
				status = "disabled";
				reg = < 0x00 0xfe300000 0x00 0x40000 >;
				interrupt-parent = < 0x04 >;
				interrupts = < 0x00 0x46 0x04 0x00 0x4a 0x04 0x00 0x4c 0x04 >;
				#stream-id-cells = < 0x01 >;
				iommus = < 0x09 0x861 >;
				snps,quirk-frame-length-adjustment = < 0x20 >;
				snps,refclk_fladj;
				snps,enable_guctl1_resume_quirk;
				snps,enable_guctl1_ipd_quirk;
				snps,xhci-stream-quirk;
				phandle = < 0x74 >;
			};
		};

		watchdog@fd4d0000 {
			compatible = "cdns,wdt-r1p2";
			status = "okay";
			interrupt-parent = < 0x04 >;
			interrupts = < 0x00 0x71 0x01 >;
			reg = < 0x00 0xfd4d0000 0x00 0x1000 >;
			timeout-sec = < 0x0a >;
			clocks = < 0x03 0x4b >;
			phandle = < 0x75 >;
		};

		ams@ffa50000 {
			compatible = "xlnx,zynqmp-ams";
			status = "okay";
			interrupt-parent = < 0x04 >;
			interrupts = < 0x00 0x38 0x04 >;
			interrupt-names = "ams-irq";
			reg = < 0x00 0xffa50000 0x00 0x800 >;
			reg-names = "ams-base";
			#address-cells = < 0x02 >;
			#size-cells = < 0x02 >;
			#io-channel-cells = < 0x01 >;
			ranges;
			clocks = < 0x03 0x46 >;
			phandle = < 0x76 >;

			ams_ps@ffa50800 {
				compatible = "xlnx,zynqmp-ams-ps";
				status = "okay";
				reg = < 0x00 0xffa50800 0x00 0x400 >;
				phandle = < 0x77 >;
			};

			ams_pl@ffa50c00 {
				compatible = "xlnx,zynqmp-ams-pl";
				status = "okay";
				reg = < 0x00 0xffa50c00 0x00 0x400 >;
				phandle = < 0x78 >;
			};
		};

		dma@fd4c0000 {
			compatible = "xlnx,dpdma";
			status = "disabled";
			reg = < 0x00 0xfd4c0000 0x00 0x1000 >;
			interrupts = < 0x00 0x7a 0x04 >;
			interrupt-parent = < 0x04 >;
			clock-names = "axi_clk";
			power-domains = < 0x28 >;
			dma-channels = < 0x06 >;
			#dma-cells = < 0x01 >;
			clocks = < 0x03 0x14 >;
			phandle = < 0x2a >;

			dma-video0channel {
				compatible = "xlnx,video0";
			};

			dma-video1channel {
				compatible = "xlnx,video1";
			};

			dma-video2channel {
				compatible = "xlnx,video2";
			};

			dma-graphicschannel {
				compatible = "xlnx,graphics";
			};

			dma-audio0channel {
				compatible = "xlnx,audio0";
			};

			dma-audio1channel {
				compatible = "xlnx,audio1";
			};
		};

		zynqmp-display@fd4a0000 {
			compatible = "xlnx,zynqmp-dpsub-1.7";
			status = "disabled";
			reg = < 0x00 0xfd4a0000 0x00 0x1000 0x00 0xfd4aa000 0x00 0x1000 0x00 0xfd4ab000 0x00 0x1000 0x00 0xfd4ac000 0x00 0x1000 >;
			reg-names = "dp\0blend\0av_buf\0aud";
			interrupts = < 0x00 0x77 0x04 >;
			interrupt-parent = < 0x04 >;
			clock-names = "dp_apb_clk\0dp_aud_clk\0dp_vtc_pixel_clk_in";
			power-domains = < 0x28 >;
			clocks = < 0x29 0x03 0x11 0x03 0x10 >;
			phandle = < 0x79 >;

			vid-layer {
				dma-names = "vid0\0vid1\0vid2";
				dmas = < 0x2a 0x00 0x2a 0x01 0x2a 0x02 >;
			};

			gfx-layer {
				dma-names = "gfx0";
				dmas = < 0x2a 0x03 >;
			};

			i2c-bus {
			};

			zynqmp_dp_snd_codec0 {
				compatible = "xlnx,dp-snd-codec";
				clock-names = "aud_clk";
				clocks = < 0x03 0x11 >;
				phandle = < 0x2d >;
			};

			zynqmp_dp_snd_pcm0 {
				compatible = "xlnx,dp-snd-pcm";
				dmas = < 0x2a 0x04 >;
				dma-names = "tx";
				phandle = < 0x2b >;
			};

			zynqmp_dp_snd_pcm1 {
				compatible = "xlnx,dp-snd-pcm";
				dmas = < 0x2a 0x05 >;
				dma-names = "tx";
				phandle = < 0x2c >;
			};

			zynqmp_dp_snd_card {
				compatible = "xlnx,dp-snd-card";
				xlnx,dp-snd-pcm = < 0x2b 0x2c >;
				xlnx,dp-snd-codec = < 0x2d >;
				phandle = < 0x7a >;
			};
		};
	};


	fclk0 {
		status = "disabled";
		compatible = "xlnx,fclk";
		clocks = < 0x03 0x47 >;
		phandle = < 0x7b >;
	};

	fclk1 {
		status = "disabled";
		compatible = "xlnx,fclk";
		clocks = < 0x03 0x48 >;
		phandle = < 0x7c >;
	};

	fclk2 {
		status = "disabled";
		compatible = "xlnx,fclk";
		clocks = < 0x03 0x49 >;
		phandle = < 0x7d >;
	};

	fclk3 {
		status = "disabled";
		compatible = "xlnx,fclk";
		clocks = < 0x03 0x4a >;
		phandle = < 0x7e >;
	};

	pss_ref_clk {
		u-boot,dm-pre-reloc;
		compatible = "fixed-clock";
		#clock-cells = < 0x00 >;
		clock-frequency = < 0x1fca055 >;
		phandle = < 0x2e >;
	};

	video_clk {
		u-boot,dm-pre-reloc;
		compatible = "fixed-clock";
		#clock-cells = < 0x00 >;
		clock-frequency = < 0x19bfcc0 >;
		phandle = < 0x2f >;
	};

	pss_alt_ref_clk {
		u-boot,dm-pre-reloc;
		compatible = "fixed-clock";
		#clock-cells = < 0x00 >;
		clock-frequency = < 0x00 >;
		phandle = < 0x30 >;
	};

	gt_crx_ref_clk {
		u-boot,dm-pre-reloc;
		compatible = "fixed-clock";
		#clock-cells = < 0x00 >;
		clock-frequency = < 0x66ff300 >;
		phandle = < 0x32 >;
	};

	aux_ref_clk {
		u-boot,dm-pre-reloc;
		compatible = "fixed-clock";
		#clock-cells = < 0x00 >;
		clock-frequency = < 0x19bfcc0 >;
		phandle = < 0x31 >;
	};

	clk {
		u-boot,dm-pre-reloc;
		#clock-cells = < 0x01 >;
		compatible = "xlnx,zynqmp-clk";
		clocks = < 0x2e 0x2f 0x30 0x31 0x32 >;
		clock-names = "pss_ref_clk\0video_clk\0pss_alt_ref_clk\0aux_ref_clk\0gt_crx_ref_clk";
		phandle = < 0x03 >;
	};

	dp_aclk {
		compatible = "fixed-clock";
		#clock-cells = < 0x00 >;
		clock-frequency = < 0x5f5e100 >;
		clock-accuracy = < 0x64 >;
		phandle = < 0x29 >;
	};

	chosen {
		bootargs = "earlycon clk_ignore_unused root=/dev/mmcblk0p2 rw rootwait cpuidle.off=1 cma=1024M";
		stdout-path = "serial0:115200n8";
	};

	aliases {
		ethernet0 = "/amba/ethernet@ff0e0000";
		i2c0 = "/amba/i2c@ff020000";
		i2c1 = "/amba/i2c@ff030000";
		serial0 = "/amba/serial@ff000000";
		serial1 = "/amba/serial@ff010000";
		spi0 = "/amba/spi@ff0f0000";
	};

	memory {
		device_type = "memory";
		reg = < 0x00 0x00 0x00 0x7ff00000 0x08 0x00 0x03 0x80000000 >;
	};

	__symbols__ {
		test = < 0x59 >;
		cpu0 = "/cpus/cpu@0";
		cpu1 = "/cpus/cpu@1";
		cpu2 = "/cpus/cpu@2";
		cpu3 = "/cpus/cpu@3";
		CPU_SLEEP_0 = "/cpus/idle-states/cpu-sleep-0";
		cpu_opp_table = "/cpu_opp_table";
		dcc = "/dcc";
		pd_usb0 = "/power-domains/pd-usb0";
		pd_usb1 = "/power-domains/pd-usb1";
		pd_sata = "/power-domains/pd-sata";
		pd_spi0 = "/power-domains/pd-spi0";
		pd_spi1 = "/power-domains/pd-spi1";
		pd_uart0 = "/power-domains/pd-uart0";
		pd_uart1 = "/power-domains/pd-uart1";
		pd_eth0 = "/power-domains/pd-eth0";
		pd_eth1 = "/power-domains/pd-eth1";
		pd_eth2 = "/power-domains/pd-eth2";
		pd_eth3 = "/power-domains/pd-eth3";
		pd_i2c0 = "/power-domains/pd-i2c0";
		pd_i2c1 = "/power-domains/pd-i2c1";
		pd_dp = "/power-domains/pd-dp";
		pd_gdma = "/power-domains/pd-gdma";
		pd_adma = "/power-domains/pd-adma";
		pd_ttc0 = "/power-domains/pd-ttc0";
		pd_ttc1 = "/power-domains/pd-ttc1";
		pd_ttc2 = "/power-domains/pd-ttc2";
		pd_ttc3 = "/power-domains/pd-ttc3";
		pd_sd0 = "/power-domains/pd-sd0";
		pd_sd1 = "/power-domains/pd-sd1";
		pd_nand = "/power-domains/pd-nand";
		pd_qspi = "/power-domains/pd-qspi";
		pd_gpio = "/power-domains/pd-gpio";
		pd_can0 = "/power-domains/pd-can0";
		pd_can1 = "/power-domains/pd-can1";
		pd_pcie = "/power-domains/pd-pcie";
		pd_gpu = "/power-domains/pd-gpu";
		ipi_mailbox_pmu1 = "/mailbox@ff990400";
		zynqmp_firmware = "/firmware/zynqmp-firmware";
		zynqmp_power = "/zynqmp-power";
		fpga_full = "/fpga-full";
		soc_revision = "/nvmem_firmware/soc_revision@0";
		pcap = "/pcap";
		rst = "/reset-controller";
		xlnx_rsa = "/zynqmp_rsa";
		xlnx_keccak_384 = "/sha384";
		amba_apu = "/amba_apu@0";
		gic = "/amba_apu@0/interrupt-controller@f9010000";
		amba = "/amba";
		can0 = "/amba/can@ff060000";
		can1 = "/amba/can@ff070000";
		cci = "/amba/cci@fd6e0000";
		fpd_dma_chan1 = "/amba/dma@fd500000";
		fpd_dma_chan2 = "/amba/dma@fd510000";
		fpd_dma_chan3 = "/amba/dma@fd520000";
		fpd_dma_chan4 = "/amba/dma@fd530000";
		fpd_dma_chan5 = "/amba/dma@fd540000";
		fpd_dma_chan6 = "/amba/dma@fd550000";
		fpd_dma_chan7 = "/amba/dma@fd560000";
		fpd_dma_chan8 = "/amba/dma@fd570000";
		gpu = "/amba/gpu@fd4b0000";
		lpd_dma_chan1 = "/amba/dma@ffa80000";
		lpd_dma_chan2 = "/amba/dma@ffa90000";
		lpd_dma_chan3 = "/amba/dma@ffaa0000";
		lpd_dma_chan4 = "/amba/dma@ffab0000";
		lpd_dma_chan5 = "/amba/dma@ffac0000";
		lpd_dma_chan6 = "/amba/dma@ffad0000";
		lpd_dma_chan7 = "/amba/dma@ffae0000";
		lpd_dma_chan8 = "/amba/dma@ffaf0000";
		mc = "/amba/memory-controller@fd070000";
		nand0 = "/amba/nand@ff100000";
		gem0 = "/amba/ethernet@ff0b0000";
		gem1 = "/amba/ethernet@ff0c0000";
		gem2 = "/amba/ethernet@ff0d0000";
		gem3 = "/amba/ethernet@ff0e0000";
		gpio = "/amba/gpio@ff0a0000";
		i2c0 = "/amba/i2c@ff020000";
		i2c1 = "/amba/i2c@ff030000";
		ocm = "/amba/memory-controller@ff960000";
		perf_monitor_ocm = "/amba/perf-monitor@ffa00000";
		pcie = "/amba/pcie@fd0e0000";
		pcie_intc = "/amba/pcie@fd0e0000/legacy-interrupt-controller";
		qspi = "/amba/spi@ff0f0000";
		rtc = "/amba/rtc@ffa60000";
		serdes = "/amba/zynqmp_phy@fd400000";
		lane0 = "/amba/zynqmp_phy@fd400000/lane0";
		lane1 = "/amba/zynqmp_phy@fd400000/lane1";
		lane2 = "/amba/zynqmp_phy@fd400000/lane2";
		lane3 = "/amba/zynqmp_phy@fd400000/lane3";
		sata = "/amba/ahci@fd0c0000";
		sdhci0 = "/amba/sdhci@ff160000";
		sdhci1 = "/amba/sdhci@ff170000";
		pinctrl0 = "/amba/pinctrl@ff180000";
		smmu = "/amba/smmu@fd800000";
		spi0 = "/amba/spi@ff040000";
		spi1 = "/amba/spi@ff050000";
		ttc0 = "/amba/timer@ff110000";
		ttc1 = "/amba/timer@ff120000";
		ttc2 = "/amba/timer@ff130000";
		ttc3 = "/amba/timer@ff140000";
		uart0 = "/amba/serial@ff000000";
		uart1 = "/amba/serial@ff010000";
		usb0 = "/amba/usb0@ff9d0000";
		dwc3_0 = "/amba/usb0@ff9d0000/dwc3@fe200000";
		usb1 = "/amba/usb1@ff9e0000";
		dwc3_1 = "/amba/usb1@ff9e0000/dwc3@fe300000";
		watchdog0 = "/amba/watchdog@fd4d0000";
		xilinx_ams = "/amba/ams@ffa50000";
		ams_ps = "/amba/ams@ffa50000/ams_ps@ffa50800";
		ams_pl = "/amba/ams@ffa50000/ams_pl@ffa50c00";
		xlnx_dpdma = "/amba/dma@fd4c0000";
		zynqmp_dpsub = "/amba/zynqmp-display@fd4a0000";
		zynqmp_dp_snd_codec0 = "/amba/zynqmp-display@fd4a0000/zynqmp_dp_snd_codec0";
		zynqmp_dp_snd_pcm0 = "/amba/zynqmp-display@fd4a0000/zynqmp_dp_snd_pcm0";
		zynqmp_dp_snd_pcm1 = "/amba/zynqmp-display@fd4a0000/zynqmp_dp_snd_pcm1";
		zynqmp_dp_snd_card0 = "/amba/zynqmp-display@fd4a0000/zynqmp_dp_snd_card";
		fclk0 = "/fclk0";
		fclk1 = "/fclk1";
		fclk2 = "/fclk2";
		fclk3 = "/fclk3";
		pss_ref_clk = "/pss_ref_clk";
		video_clk = "/video_clk";
		pss_alt_ref_clk = "/pss_alt_ref_clk";
		gt_crx_ref_clk = "/gt_crx_ref_clk";
		aux_ref_clk = "/aux_ref_clk";
		clk = "/clk";
		dp_aclk = "/dp_aclk";
	};
};
